VERSION "RLDCU"

NS_ :

BS_:

BU_: RLDCU

BO_ 3221225472 VECTOR__INDEPENDENT_SIG_MSG: 0 Vector__XXX
 SG_ CrashOtptSts : 0|8@0+ (1,0) [0|255] "" Vector__XXX
 SG_ SigGroup_232_ChkSm : 0|8@0+ (1,0) [0|255] "" Vector__XXX
 SG_ SigGroup_232_RlngCtr : 0|4@0+ (1,0) [0|15] "" Vector__XXX

BO_ 906 XCU_BodyCMD1_100mixed_GW: 8 Vector__XXX
 SG_ SwBkLghtCmd : 22|7@0+ (1,0) [0|100] "%" Vector__XXX

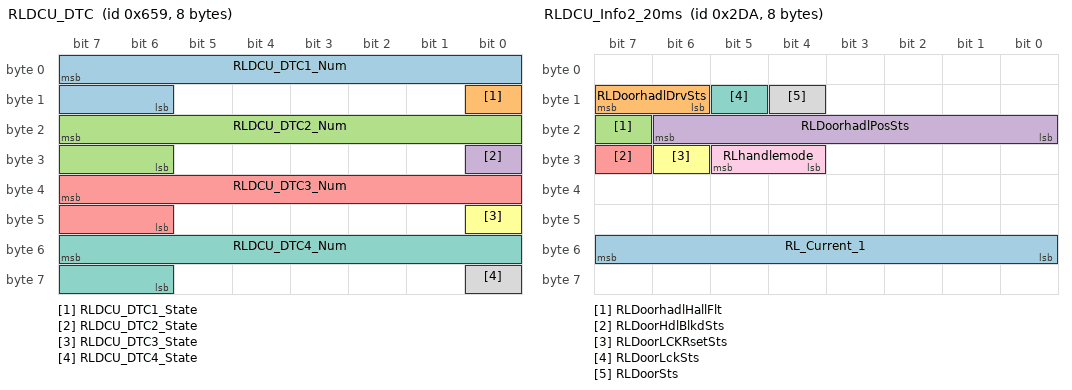
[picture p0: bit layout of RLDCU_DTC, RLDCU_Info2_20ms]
BO_ 1625 RLDCU_DTC: 8 RLDCU
 SG_ RLDCU_DTC1_Num : 7|10@0+ (1,0) [0|1023] "" Vector__XXX
 SG_ RLDCU_DTC1_State : 8|1@0+ (1,0) [0|1] "" Vector__XXX
 SG_ RLDCU_DTC2_Num : 23|10@0+ (1,0) [0|1023] "" Vector__XXX
 SG_ RLDCU_DTC2_State : 24|1@0+ (1,0) [0|1] "" Vector__XXX
 SG_ RLDCU_DTC3_Num : 39|10@0+ (1,0) [0|1023] "" Vector__XXX
 SG_ RLDCU_DTC3_State : 40|1@0+ (1,0) [0|1] "" Vector__XXX
 SG_ RLDCU_DTC4_Num : 55|10@0+ (1,0) [0|1023] "" Vector__XXX
 SG_ RLDCU_DTC4_State : 56|1@0+ (1,0) [0|1] "" Vector__XXX

BO_ 1386 RLDCU_Info1_100ms: 32 RLDCU
 SG_ LChildProtnLckDrvFlt : 34|1@0+ (1,0) [0|1] "" Vector__XXX
 SG_ LChildProtnLckDrvSts : 18|2@0+ (1,0) [0|3] "" Vector__XXX
 SG_ LChildProtnLckFlt : 16|1@0+ (1,0) [0|1] "" Vector__XXX
 SG_ LChildProtnLckSts : 23|1@0+ (1,0) [0|1] "" Vector__XXX
 SG_ LChildProtnLckThrmlProtnSts : 35|1@0+ (1,0) [0|1] "" Vector__XXX
 SG_ RLCinchabusests : 76|1@0+ (1,0) [0|1] "" Vector__XXX
 SG_ RLDCUconfigureSts : 66|3@0+ (1,0) [0|7] "" Vector__XXX
 SG_ RLDCUCrashSts : 79|1@0+ (1,0) [0|1] "" Vector__XXX
 SG_ RLDoor_BackLghtDrvSts : 57|7@0+ (1,0) [0|100] "%" Vector__XXX
 SG_ RLDoor_BackLghtFlrSts : 59|2@0+ (1,0) [0|3] "" Vector__XXX
 SG_ RLDoorCinchSts : 15|2@0+ (1,0) [0|3] "" Vector__XXX
 SG_ RLDoorHadlLghtDrvSts : 62|1@0+ (1,0) [0|1] "" Vector__XXX
 SG_ RLDoorHadlLghtFlrSts : 61|2@0+ (1,0) [0|3] "" Vector__XXX
 SG_ RLDoorhadlMotorFlt : 39|1@0+ (1,0) [0|1] "" Vector__XXX
 SG_ RLDoorLckUnlckDrvSts : 33|2@0+ (1,0) [0|3] "" Vector__XXX
 SG_ RLDoorLightSts : 78|1@0+ (1,0) [0|1] "" Vector__XXX
 SG_ RLDoorligtsFlt : 75|1@0+ (1,0) [0|1] "" Vector__XXX
 SG_ RLDoorligtsSts : 77|1@0+ (1,0) [0|1] "" Vector__XXX
 SG_ RLDoorPawlSts : 22|1@0+ (1,0) [0|1] "" Vector__XXX
 SG_ RLDoorPullCircuitFlt : 19|1@0+ (1,0) [0|1] "" Vector__XXX
 SG_ RLDoorPullDrvFlt : 20|1@0+ (1,0) [0|1] "" Vector__XXX
 SG_ RLDoorPullDrvSts : 13|2@0+ (1,0) [0|3] "" Vector__XXX
 SG_ RLDoorRatchetSts : 21|1@0+ (1,0) [0|1] "" Vector__XXX
 SG_ RLDoorThrmlProtnSts : 36|1@0+ (1,0) [0|1] "" Vector__XXX
 SG_ RLDoorUnlckCircuitFlt : 38|1@0+ (1,0) [0|1] "" Vector__XXX
 SG_ RLDoorUnlckDrvFlt : 37|1@0+ (1,0) [0|1] "" Vector__XXX
 SG_ RLDoorWinHallFlt : 74|2@0+ (1,0) [0|3] "" Vector__XXX
 SG_ RLWdwReqRes : 28|4@0+ (1,0) [0|15] "" Vector__XXX
 SG_ RLWndAnti_PnchSts : 46|1@0+ (1,0) [0|1] "" Vector__XXX
 SG_ RLWndInhSts : 63|1@0+ (1,0) [0|1] "" Vector__XXX
 SG_ RLWndInitnSts : 47|1@0+ (1,0) [0|1] "" Vector__XXX
 SG_ RLWndMotorFlt : 40|1@0+ (1,0) [0|1] "" Vector__XXX
 SG_ RLWndPcntPos : 54|7@0+ (1,0) [0|100] "%" Vector__XXX
 SG_ RLWndRunSts : 43|3@0+ (1,0) [0|7] "" Vector__XXX
 SG_ RLWndSts : 45|2@0+ (1,0) [0|3] "" Vector__XXX
 SG_ RLWndSwSts : 31|3@0+ (1,0) [0|7] "" Vector__XXX
 SG_ RLWndSwStuckFlt : 24|1@0+ (1,0) [0|1] "" Vector__XXX
 SG_ RLWndThrmlProtnSts : 55|1@0+ (1,0) [0|1] "" Vector__XXX
 SG_ SigGroup_0x56A_ChkSm : 7|8@0+ (1,0) [0|255] "" Vector__XXX
 SG_ SigGroup_0x56A_RlngCtr : 11|4@0+ (1,0) [0|15] "" Vector__XXX

BO_ 730 RLDCU_Info2_20ms: 8 RLDCU
 SG_ RL_Current_1 : 55|8@0+ (1,0) [0|255] "" Vector__XXX
 SG_ RLDoorhadlDrvSts : 15|2@0+ (1,0) [0|3] "" Vector__XXX
 SG_ RLDoorhadlHallFlt : 23|1@0+ (1,0) [0|1] "" Vector__XXX
 SG_ RLDoorhadlPosSts : 22|7@0+ (1,0) [0|100] "%" Vector__XXX
 SG_ RLDoorHdlBlkdSts : 31|1@0+ (1,0) [0|1] "" Vector__XXX
 SG_ RLDoorLCKRsetSts : 30|1@0+ (1,0) [0|1] "" Vector__XXX
 SG_ RLDoorLckSts : 13|1@0+ (1,0) [0|1] "" Vector__XXX
 SG_ RLDoorSts : 12|1@0+ (1,0) [0|1] "" Vector__XXX
 SG_ RLhandlemode : 29|2@0+ (1,0) [0|3] "" Vector__XXX

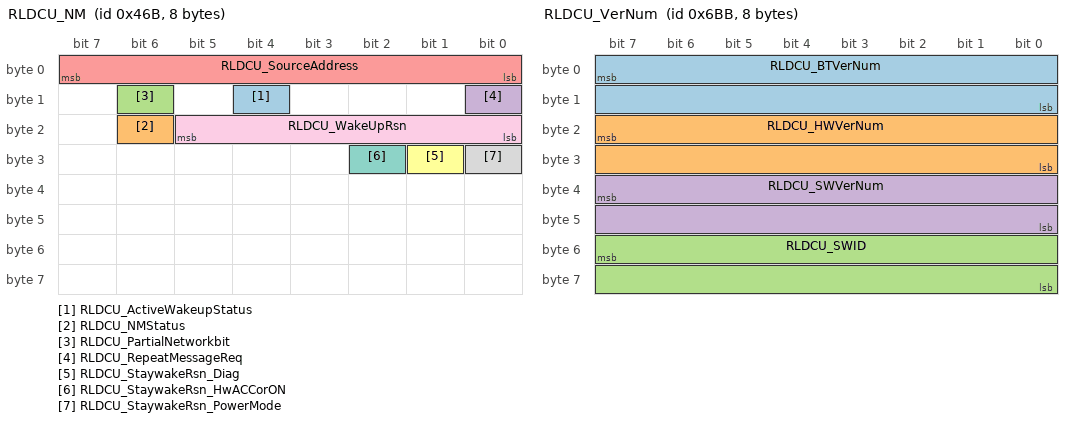
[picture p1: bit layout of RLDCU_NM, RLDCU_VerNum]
BO_ 1131 RLDCU_NM: 8 RLDCU
 SG_ RLDCU_ActiveWakeupStatus : 12|1@0+ (1,0) [0|1] "" Vector__XXX
 SG_ RLDCU_NMStatus : 22|1@0+ (1,0) [0|1] "" Vector__XXX
 SG_ RLDCU_PartialNetworkbit : 14|1@0+ (1,0) [0|1] "" Vector__XXX
 SG_ RLDCU_RepeatMessageReq : 8|1@0+ (1,0) [0|1] "" Vector__XXX
 SG_ RLDCU_SourceAddress : 7|8@0+ (1,0) [0|255] "" Vector__XXX
 SG_ RLDCU_StaywakeRsn_Diag : 25|1@0+ (1,0) [0|1] "" Vector__XXX
 SG_ RLDCU_StaywakeRsn_HwACCorON : 26|1@0+ (1,0) [0|1] "" Vector__XXX
 SG_ RLDCU_StaywakeRsn_PowerMode : 24|1@0+ (1,0) [0|1] "" Vector__XXX
 SG_ RLDCU_WakeUpRsn : 21|6@0+ (1,0) [0|63] "" Vector__XXX

BO_ 1723 RLDCU_VerNum: 8 RLDCU
 SG_ RLDCU_BTVerNum : 7|16@0+ (1,0) [0|65535] "" Vector__XXX
 SG_ RLDCU_HWVerNum : 23|16@0+ (1,0) [0|65535] "" Vector__XXX
 SG_ RLDCU_SWID : 55|16@0+ (1,0) [0|65535] "" Vector__XXX
 SG_ RLDCU_SWVerNum : 39|16@0+ (1,0) [0|65535] "" Vector__XXX

BO_ 1887 UDS_DiagResp_RLDCU_FD: 64 RLDCU

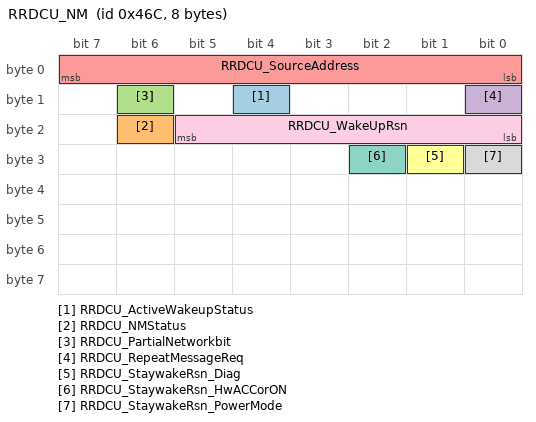
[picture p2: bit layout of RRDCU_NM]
BO_ 1132 RRDCU_NM: 8 Vector__XXX
 SG_ RRDCU_ActiveWakeupStatus : 12|1@0+ (1,0) [0|1] ""  RLDCU
 SG_ RRDCU_NMStatus : 22|1@0+ (1,0) [0|1] ""  RLDCU
 SG_ RRDCU_PartialNetworkbit : 14|1@0+ (1,0) [0|1] ""  RLDCU
 SG_ RRDCU_RepeatMessageReq : 8|1@0+ (1,0) [0|1] ""  RLDCU
 SG_ RRDCU_SourceAddress : 7|8@0+ (1,0) [0|255] ""  RLDCU
 SG_ RRDCU_StaywakeRsn_Diag : 25|1@0+ (1,0) [0|1] ""  RLDCU
 SG_ RRDCU_StaywakeRsn_HwACCorON : 26|1@0+ (1,0) [0|1] ""  RLDCU
 SG_ RRDCU_StaywakeRsn_PowerMode : 24|1@0+ (1,0) [0|1] ""  RLDCU
 SG_ RRDCU_WakeUpRsn : 21|6@0+ (1,0) [0|63] ""  RLDCU

BO_ 2015 UDS_FuncDiagReq_FD: 8 Vector__XXX

BO_ 1879 UDS_PhyDiagReq_RLDCU_FD: 64 Vector__XXX

CM_ BO_ 3221225472 "This is a message for not used signals, created by Vector CANdb++ DBC OLE DB Provider.";
CM_ SG_ 3221225472 CrashOtptSts "Crash Output Status
碰撞输出状态
注：碰撞发生后，此信号持续发送400ms（20ms间隔发送20次），之后恢复原周期（200ms）；
bit0表示前碰，bit1表示左侧碰撞，bit2表示右侧碰撞，bit3表示后碰，bit4表示翻转
则
0(00000000)表示没有碰撞，
1(00000001)表示只有前碰
2(00000010)表示只有左侧碰撞
4(00000100)表示只有右侧碰撞
8(00001000)表示只有后碰
0X10(00010000)表示翻转";
CM_ SG_ 1625 RLDCU_DTC1_Num "DTC Number
DTC序号";
CM_ SG_ 1625 RLDCU_DTC1_State "DTC State
故障状态";
CM_ SG_ 1625 RLDCU_DTC2_Num "DTC Number
DTC序号";
CM_ SG_ 1625 RLDCU_DTC2_State "DTC State
故障状态";
CM_ SG_ 1625 RLDCU_DTC3_Num "DTC Number
DTC序号";
CM_ SG_ 1625 RLDCU_DTC3_State "DTC State
故障状态";
CM_ SG_ 1625 RLDCU_DTC4_Num "DTC Number
DTC序号";
CM_ SG_ 1625 RLDCU_DTC4_State "DTC State
故障状态";
CM_ SG_ 1386 LChildProtnLckDrvFlt "Left child Protection lock  drive Fault
左侧儿童锁驱动故障";
CM_ SG_ 1386 LChildProtnLckDrvSts "Left child Protection lock  drive status
左侧儿童锁驱动状态";
CM_ SG_ 1386 LChildProtnLckFlt "left child Protection lock fault
左儿童锁故障";
CM_ SG_ 1386 LChildProtnLckSts "Left Child Protection Lock Status
左侧儿童锁状态";
CM_ SG_ 1386 LChildProtnLckThrmlProtnSts "Left child Protection  lock Thermal Protection State
左侧儿童锁热保护状态";
CM_ SG_ 1386 RLCinchabusests "Cinchabusests
自吸锁滥用状态";
CM_ SG_ 1386 RLDCUconfigureSts "RLDCU配置状态
RLDCUconfigureSts";
CM_ SG_ 1386 RLDCUCrashSts "碰撞状态
RLDCU Crash  Sts";
CM_ SG_ 1386 RLDoor_BackLghtDrvSts "Rear  Left Door Back Light DrvSts
左后门背光驱动状态";
CM_ SG_ 1386 RLDoor_BackLghtFlrSts "Rear Left Door Back Light FlrSts
左后门背光故障状态";
CM_ SG_ 1386 RLDoorCinchSts "Rear Left Door Cinch Status";
CM_ SG_ 1386 RLDoorHadlLghtDrvSts "Rear Left Door Handle LightDriveStaus
左后门把手灯驱动状态";
CM_ SG_ 1386 RLDoorHadlLghtFlrSts "Rear Left Door Handle LightFailureStaus
左后门把手灯故障状态";
CM_ SG_ 1386 RLDoorhadlMotorFlt "左后门把手电机故障
Rear Left Door Handle Motor Fault";
CM_ SG_ 1386 RLDoorLckUnlckDrvSts "Rear Left Door Lock Unlock Drive Status
左后门解闭锁驱动状态";
CM_ SG_ 1386 RLDoorLightSts "左后门灯状态
RLDoorLightSts";
CM_ SG_ 1386 RLDoorligtsFlt "RLDoorligtsFlt
门灯故障状态";
CM_ SG_ 1386 RLDoorligtsSts "RLDoorligtsSts
门灯状态";
CM_ SG_ 1386 RLDoorPawlSts "Rear Left Door Pawl Status
左后锁棘爪状态";
CM_ SG_ 1386 RLDoorPullCircuitFlt "Rear Left Door Pull Circuit Fault
左后门自吸电路故障";
CM_ SG_ 1386 RLDoorPullDrvFlt "Rear Left Door Pull Drive Fault
左后门自吸驱动故障";
CM_ SG_ 1386 RLDoorPullDrvSts "Rear Left Door Pull Drive Status
左后自吸驱动状态";
CM_ SG_ 1386 RLDoorRatchetSts "Rear Left Door Ratchet Status
左后门锁棘轮状态";
CM_ SG_ 1386 RLDoorThrmlProtnSts "Rear Left Door Thermal Protection State
左后门锁热保护状态";
CM_ SG_ 1386 RLDoorUnlckCircuitFlt "Rear Left Door Unlock Circuit Fault
左后门锁解锁电路故障";
CM_ SG_ 1386 RLDoorUnlckDrvFlt "Rear Left Door Unlock Drive Fault
左后门解锁驱动故障";
CM_ SG_ 1386 RLDoorWinHallFlt "左后车窗霍尔故障状态
RL Door Windows Hall Fault status";
CM_ SG_ 1386 RLWdwReqRes "Rear Left Window Request Result
左后车窗请求结果";
CM_ SG_ 1386 RLWndAnti_PnchSts "Rear Left windowAnti_Pinch Status
左后车窗防夹触发";
CM_ SG_ 1386 RLWndInhSts "Rear Left Window Inhibit Status
左后车窗防夹抑制状态";
CM_ SG_ 1386 RLWndInitnSts "Rear Left Window Initialization Status
左后车窗初始化状态";
CM_ SG_ 1386 RLWndMotorFlt "Rear Left Window Motor Fault
左后车窗电机故障状态";
CM_ SG_ 1386 RLWndPcntPos "Rear Left Window Percentage Position
左后车窗开度0%(全关)100%(全开)";
CM_ SG_ 1386 RLWndRunSts "Rear Left Window Run Status
左后车窗运行状态";
CM_ SG_ 1386 RLWndSts "Rear Left Window Status
左后车窗状态";
CM_ SG_ 1386 RLWndSwSts "Rear Left Window Switch Status
本地左后车窗开关";
CM_ SG_ 1386 RLWndSwStuckFlt "Rear Left Window Switch Stuck Fault
本地左后车窗开关粘连故障";
CM_ SG_ 1386 RLWndThrmlProtnSts "Rear Left Window Thermal Protection State
左后车窗热保护状态";
CM_ SG_ 1386 SigGroup_0x56A_ChkSm "CheckSum
CRC校验";
CM_ SG_ 1386 SigGroup_0x56A_RlngCtr "RollingCounter
滚动计数器";
CM_ SG_ 730 RL_Current_1 "左后电流值1";
CM_ SG_ 730 RLDoorhadlDrvSts "左后门把手驱动状态
Rear Left Door Handle Drive Status";
CM_ SG_ 730 RLDoorhadlHallFlt "左后门把手霍尔故障状态
Rear Left Door Handle Hall Fault status";
CM_ SG_ 730 RLDoorhadlPosSts "Rear Left Door Handle Pos status
左后门把手位置状态0%(全关)100%(全开)";
CM_ SG_ 730 RLDoorHdlBlkdSts "Rear Left  Door Handle Blocked Status 左后门把手受阻信号";
CM_ SG_ 730 RLDoorLCKRsetSts "RLDoorLCKRsetSts
左后自吸锁复位状态";
CM_ SG_ 730 RLDoorLckSts "Rear Left Door Lock Status
左后门锁状态信号";
CM_ SG_ 730 RLDoorSts "Rear Left Door Status
左后门状态信号";
CM_ SG_ 730 RLhandlemode "RL把手模式
handlemode";
CM_ SG_ 1131 RLDCU_ActiveWakeupStatus "Active Wakeup Bit
主动唤醒标志位";
CM_ SG_ 1131 RLDCU_NMStatus "Network Management State
指示网络管理状态";
CM_ SG_ 1131 RLDCU_PartialNetworkbit "Partial Network Bit
PN标志位";
CM_ SG_ 1131 RLDCU_RepeatMessageReq "Repeat Message Request
重复报文发送请求";
CM_ SG_ 1131 RLDCU_SourceAddress "Source ECU Address
ECU源地址";
CM_ SG_ 1131 RLDCU_StaywakeRsn_Diag "stay wake reason diagnosis
保持唤醒原因诊断模式";
CM_ SG_ 1131 RLDCU_StaywakeRsn_HwACCorON "stay wake reason hardwire ACC or ON
保持唤醒原因硬线ACC或ON有效";
CM_ SG_ 1131 RLDCU_StaywakeRsn_PowerMode "stay wake reason power mode ACC or ON
保持唤醒原因总线信号PowerMode为ACC或ON";
CM_ SG_ 1131 RLDCU_WakeUpRsn "RLDCU wake up reason
RLDCU 唤醒原因";
CM_ SG_ 1723 RLDCU_BTVerNum "BOOT Version Number
BOOT版本号";
CM_ SG_ 1723 RLDCU_HWVerNum "HardWare Version Number
硬件版本号";
CM_ SG_ 1723 RLDCU_SWID "Software ID
软件ID";
CM_ SG_ 1723 RLDCU_SWVerNum "SoftWare Version Number
软件版本号";
CM_ BO_ 1887 "当前定义的64个字节为最大诊断报文收发长度，不是固定长度，CANFD控制器应根据理想企标定义收发诊断报文";
CM_ SG_ 1132 RRDCU_ActiveWakeupStatus "Active Wakeup Bit
主动唤醒标志位";
CM_ SG_ 1132 RRDCU_NMStatus "Network Management State
指示网络管理状态";
CM_ SG_ 1132 RRDCU_PartialNetworkbit "Partial Network Bit
PN标志位";
CM_ SG_ 1132 RRDCU_RepeatMessageReq "Repeat Message Request
重复报文发送请求";
CM_ SG_ 1132 RRDCU_SourceAddress "Source ECU Address
ECU源地址";
CM_ SG_ 1132 RRDCU_StaywakeRsn_Diag "stay wake reason diagnosis
保持唤醒原因诊断模式";
CM_ SG_ 1132 RRDCU_StaywakeRsn_HwACCorON "stay wake reason hardwire ACC or ON
保持唤醒原因硬线ACC或ON有效";
CM_ SG_ 1132 RRDCU_StaywakeRsn_PowerMode "stay wake reason power mode ACC or ON
保持唤醒原因总线信号PowerMode为ACC或ON";
CM_ SG_ 1132 RRDCU_WakeUpRsn "RRDCU wake up reason
RRDCU 唤醒原因";
CM_ BO_ 1879 "当前定义的64个字节为最大诊断报文收发长度，不是固定长度，CANFD控制器应根据理想企标定义收发诊断报文";
BA_DEF_  "BaudRateCANFD" INT 1000 10000000;
BA_DEF_  "Baudrate" INT 1000 1000000;
BA_DEF_  "BusType" STRING ;
BA_DEF_  "DBName" STRING ;
BA_DEF_  "Manufacturer" STRING ;
BA_DEF_  "NmAsrBaseAddress" HEX 0 65535;
BA_DEF_  "NmAsrCanMsgCycleTime" INT 0 65535;
BA_DEF_  "NmAsrMessageCount" INT 0 255;
BA_DEF_  "NmAsrRepeatMessageTime" INT 0 65535;
BA_DEF_  "NmAsrTimeoutTime" INT 0 65535;
BA_DEF_  "NmAsrWaitBusSleepTime" INT 0 65535;
BA_DEF_  "ProtocolType" STRING ;
BA_DEF_ BU_  "ILUsed" ENUM  "No","Yes";
BA_DEF_ BU_  "NmAsrCanMsgReducedTime" INT 0 65535;
BA_DEF_ BU_  "NmAsrNode" ENUM  "No","Yes";
BA_DEF_ BO_  "CANFD_BRS" ENUM  "0","1";
BA_DEF_ BO_  "DiagConnection" INT 0 65535;
BA_DEF_ BO_  "DiagRequest" ENUM  "No","Yes";
BA_DEF_ BO_  "DiagResponse" ENUM  "No","Yes";
BA_DEF_ BO_  "DiagState" ENUM  "No","Yes";
BA_DEF_ BO_  "GenMsgCycleTime" INT 0 300000;
BA_DEF_ BO_  "GenMsgDelayTime" INT 0 300000;
BA_DEF_ BO_  "GenMsgILSupport" ENUM  "No","Yes";
BA_DEF_ BO_  "GenMsgSendType" ENUM  "cyclic","spontaneous","cyclicIfActive","spontaneousWithDelay","cyclicAndSpontaneous","cyclicAndSpontaneousWithDelay","IfActive","NoMsgSendType";
BA_DEF_ BO_  "GenMsgStartDelayTime" INT 0 300000;
BA_DEF_ BO_  "NmAsrMessage" ENUM  "No","Yes";
BA_DEF_ BO_  "VFrameFormat" ENUM  "StandardCAN","ExtendedCAN","reserved","J1939PG","reserved","reserved","reserved","reserved","reserved","reserved","reserved","reserved","reserved","reserved","StandardCAN_FD","ExtendedCAN_FD";
BA_DEF_ SG_  "GenSigSendType" ENUM  "Cyclic","OnWrite","OnWriteWithRepetition","OnChange","OnChangeWithRepetition","IfActive","IfActiveWithRepetition","NoSigSendType";
BA_DEF_ SG_  "GenSigStartValue" INT 0 2147483647;
BA_DEF_DEF_  "BaudRateCANFD" 2000000;
BA_DEF_DEF_  "Baudrate" 500000;
BA_DEF_DEF_  "BusType" "";
BA_DEF_DEF_  "DBName" "";
BA_DEF_DEF_  "Manufacturer" "Vector";
BA_DEF_DEF_  "NmAsrBaseAddress" 1024;
BA_DEF_DEF_  "NmAsrCanMsgCycleTime" 500;
BA_DEF_DEF_  "NmAsrMessageCount" 255;
BA_DEF_DEF_  "NmAsrRepeatMessageTime" 1500;
BA_DEF_DEF_  "NmAsrTimeoutTime" 2000;
BA_DEF_DEF_  "NmAsrWaitBusSleepTime" 5000;
BA_DEF_DEF_  "ProtocolType" "";
BA_DEF_DEF_  "ILUsed" "Yes";
BA_DEF_DEF_  "NmAsrCanMsgReducedTime" 50;
BA_DEF_DEF_  "NmAsrNode" "Yes";
BA_DEF_DEF_  "CANFD_BRS" "1";
BA_DEF_DEF_  "DiagConnection" 57346;
BA_DEF_DEF_  "DiagRequest" "No";
BA_DEF_DEF_  "DiagResponse" "No";
BA_DEF_DEF_  "DiagState" "No";
BA_DEF_DEF_  "GenMsgCycleTime" 0;
BA_DEF_DEF_  "GenMsgDelayTime" 0;
BA_DEF_DEF_  "GenMsgILSupport" "Yes";
BA_DEF_DEF_  "GenMsgSendType" "";
BA_DEF_DEF_  "GenMsgStartDelayTime" 0;
BA_DEF_DEF_  "NmAsrMessage" "No";
BA_DEF_DEF_  "VFrameFormat" "J1939PG";
BA_DEF_DEF_  "GenSigSendType" "Cyclic";
BA_DEF_DEF_  "GenSigStartValue" 0;
BA_ "BusType" "CAN FD";
BA_ "ProtocolType" "CAN";
BA_ "DBName" "RLDCU_BDCAN1_Ctrl";
BA_ "VFrameFormat" BO_ 906 14;
BA_ "GenMsgCycleTime" BO_ 1625 1000;
BA_ "GenMsgSendType" BO_ 1625 0;
BA_ "VFrameFormat" BO_ 1625 14;
BA_ "GenMsgCycleTime" BO_ 1386 100;
BA_ "GenMsgSendType" BO_ 1386 0;
BA_ "GenMsgStartDelayTime" BO_ 1386 10;
BA_ "VFrameFormat" BO_ 1386 14;
BA_ "GenMsgCycleTime" BO_ 730 20;
BA_ "GenMsgSendType" BO_ 730 0;
BA_ "VFrameFormat" BO_ 730 14;
BA_ "GenMsgDelayTime" BO_ 1131 500;
BA_ "GenMsgSendType" BO_ 1131 1;
BA_ "NmAsrMessage" BO_ 1131 1;
BA_ "VFrameFormat" BO_ 1131 0;
BA_ "GenMsgCycleTime" BO_ 1723 5000;
BA_ "GenMsgSendType" BO_ 1723 0;
BA_ "GenMsgStartDelayTime" BO_ 1723 50;
BA_ "VFrameFormat" BO_ 1723 14;
BA_ "DiagConnection" BO_ 1887 37;
BA_ "DiagResponse" BO_ 1887 1;
BA_ "GenMsgDelayTime" BO_ 1887 20;
BA_ "GenMsgSendType" BO_ 1887 1;
BA_ "VFrameFormat" BO_ 1887 14;
BA_ "GenMsgDelayTime" BO_ 1132 500;
BA_ "GenMsgSendType" BO_ 1132 1;
BA_ "NmAsrMessage" BO_ 1132 1;
BA_ "VFrameFormat" BO_ 1132 0;
BA_ "DiagConnection" BO_ 2015 49;
BA_ "DiagState" BO_ 2015 1;
BA_ "GenMsgDelayTime" BO_ 2015 20;
BA_ "GenMsgSendType" BO_ 2015 1;
BA_ "VFrameFormat" BO_ 2015 14;
BA_ "DiagConnection" BO_ 1879 37;
BA_ "DiagRequest" BO_ 1879 1;
BA_ "GenMsgDelayTime" BO_ 1879 20;
BA_ "GenMsgSendType" BO_ 1879 1;
BA_ "VFrameFormat" BO_ 1879 14;
BA_ "GenSigSendType" SG_ 3221225472 CrashOtptSts 2;
BA_ "GenSigStartValue" SG_ 1386 RLWndPcntPos 127;
BA_ "GenSigStartValue" SG_ 1386 RLWndRunSts 3;
BA_ "GenSigStartValue" SG_ 1386 RLWndSts 3;
BA_ "GenSigSendType" SG_ 1131 RLDCU_ActiveWakeupStatus 1;
BA_ "GenSigSendType" SG_ 1131 RLDCU_NMStatus 1;
BA_ "GenSigSendType" SG_ 1131 RLDCU_PartialNetworkbit 1;
BA_ "GenSigSendType" SG_ 1131 RLDCU_RepeatMessageReq 1;
BA_ "GenSigSendType" SG_ 1131 RLDCU_SourceAddress 1;
BA_ "GenSigSendType" SG_ 1131 RLDCU_StaywakeRsn_Diag 1;
BA_ "GenSigSendType" SG_ 1131 RLDCU_StaywakeRsn_HwACCorON 1;
BA_ "GenSigSendType" SG_ 1131 RLDCU_StaywakeRsn_PowerMode 1;
BA_ "GenSigSendType" SG_ 1131 RLDCU_WakeUpRsn 1;
BA_ "GenSigStartValue" SG_ 1723 RLDCU_SWID 65535;
BA_ "GenSigSendType" SG_ 1132 RRDCU_ActiveWakeupStatus 1;
BA_ "GenSigSendType" SG_ 1132 RRDCU_NMStatus 1;
BA_ "GenSigSendType" SG_ 1132 RRDCU_PartialNetworkbit 1;
BA_ "GenSigSendType" SG_ 1132 RRDCU_RepeatMessageReq 1;
BA_ "GenSigSendType" SG_ 1132 RRDCU_SourceAddress 1;
BA_ "GenSigSendType" SG_ 1132 RRDCU_StaywakeRsn_Diag 1;
BA_ "GenSigSendType" SG_ 1132 RRDCU_StaywakeRsn_HwACCorON 1;
BA_ "GenSigSendType" SG_ 1132 RRDCU_StaywakeRsn_PowerMode 1;
BA_ "GenSigSendType" SG_ 1132 RRDCU_WakeUpRsn 1;
VAL_ 3221225472 CrashOtptSts 0 "NoDplCrsh" 1 "FrtDplCrsh" 2 "DrvrDplCrsh" 3 "Drvr_FrtDplCrsh" 4 "PsngDplCrsh" 5 "PsngFrtDplCrsh" 6 "Drvr_PsngDplCrsh" 7 "Drvr_Psng_FrtDplCrsh" 8 "Rr_DplCrsh" 9 "Rr_FrtDplCrsh" 10 "Rr_DrvrDplCrsh" 11 "Rr_Drvr_FrtDplCrsh" 12 "Rr_PsngDplCrsh" 13 "Rr_Psng_FrtDplCrsh" 14 "Rr_Psng_DrvrDplCrsh" 15 "Rr_Psng_Drv_FrtDplCrsh" 16 "Rlov_DplCrsh" 17 "Rlov_FrtDplCrsh" 18 "Rlov_DrvrSideDplCrsh" 19 "Rlov_Drvr_FrtDplCrsh" 20 "Rlov_PsngDpl Crsh" 21 "Rlov_Psng_FrtDplCrsh" 22 "Rlov_Psng_DrvrDplCrsh" 23 "Rlov_Psng_Drvr_FrtDplCrsh" 24 "Rlov_RrSideDplCrsh" 25 "Rlov_Rr_FrtDplCrsh" 26 "Rlov_Rr_DrvrDplCrsh" 27 "Rlov_Rr_Drvr_FrtDplCrsh" 28 "Rlov_Rr_PsngDplCrsh" 29 "Rlov_Rr_Psng_FrtDplCrsh" 30 "Rlov_Rr_Psng_DrvrDplCrsh" 31 "Rlov_Rr_Psng_Drvr_FrtDplCrsh" 255 "Invalid" ;
VAL_ 1625 RLDCU_DTC1_State 0 "Normal" 1 "Fault" ;
VAL_ 1625 RLDCU_DTC2_State 0 "Normal" 1 "Fault" ;
VAL_ 1625 RLDCU_DTC3_State 0 "Normal" 1 "Fault" ;
VAL_ 1625 RLDCU_DTC4_State 0 "Normal" 1 "Fault" ;
VAL_ 1386 LChildProtnLckDrvFlt 0 "Normal" 1 "Failure" ;
VAL_ 1386 LChildProtnLckDrvSts 0 "Inactive" 1 "lock" 2 "unlock" 3 "reserve" ;
VAL_ 1386 LChildProtnLckFlt 0 "Normal" 1 "Failure" ;
VAL_ 1386 LChildProtnLckSts 0 "Unlocked
" 1 "Locked" ;
VAL_ 1386 LChildProtnLckThrmlProtnSts 0 "No Error" 1 "Error" ;
VAL_ 1386 RLCinchabusests 0 "normal" 1 "active" ;
VAL_ 1386 RLDCUconfigureSts 0 "X01" 1 "X02" 2 "X03" ;
VAL_ 1386 RLDCUCrashSts 0 "NO crash" 1 "crash" ;
VAL_ 1386 RLDoor_BackLghtDrvSts 127 "Invalid" ;
VAL_ 1386 RLDoor_BackLghtFlrSts 0 "No Failure" 1 "Open Circuit" 2 "Short Circuit" 3 "Reserved" ;
VAL_ 1386 RLDoorCinchSts 0 "Locked" 1 "Cinching" 2 "Semi-lock" 3 "Unlocked" ;
VAL_ 1386 RLDoorHadlLghtDrvSts 0 "Inactive" 1 "Active" ;
VAL_ 1386 RLDoorHadlLghtFlrSts 0 "No Failure" 1 "Open Circuit" 2 "Short Circuit" 3 "Reserved" ;
VAL_ 1386 RLDoorhadlMotorFlt 0 "Normal" 1 "Failure" ;
VAL_ 1386 RLDoorLckUnlckDrvSts 0 "Inactive" 1 "lock" 2 "unlock" 3 "reserve" ;
VAL_ 1386 RLDoorLightSts 0 "OFF" 1 "ON" ;
VAL_ 1386 RLDoorligtsFlt 0 "Normal" 1 "Fault" ;
VAL_ 1386 RLDoorligtsSts 0 "OFF" 1 "ON" ;
VAL_ 1386 RLDoorPawlSts 0 "Closed" 1 "Ajar" ;
VAL_ 1386 RLDoorPullCircuitFlt 0 "Normal" 1 "Failure" ;
VAL_ 1386 RLDoorPullDrvFlt 0 "Normal" 1 "Failure" ;
VAL_ 1386 RLDoorPullDrvSts 0 "Stop" 1 "Forward Driving" 2 "Reverse Driving" 3 "Pull in disabled" ;
VAL_ 1386 RLDoorRatchetSts 0 "Closed" 1 "Ajar" ;
VAL_ 1386 RLDoorThrmlProtnSts 0 "No Error" 1 "Error" ;
VAL_ 1386 RLDoorUnlckCircuitFlt 0 "Normal" 1 "Failure" ;
VAL_ 1386 RLDoorUnlckDrvFlt 0 "Normal" 1 "Failure" ;
VAL_ 1386 RLDoorWinHallFlt 0 "Normal" 1 "1 hall Fault" 2 "2 hall Fault" 3 "all hall Fault" ;
VAL_ 1386 RLWdwReqRes 0 "No Demand" 1 "Success" 2 "Fail" 3 "In Responding" 4 "Stop By Local SW" 5 "Stop By Anti-Reverse" 6 "Stop By System Fault" ;
VAL_ 1386 RLWndAnti_PnchSts 0 "Non anti_pinch status" 1 "In Anti_pinch status" ;
VAL_ 1386 RLWndInhSts 0 "Not Obs Inhibit status" 1 "Obs Inhibit status" ;
VAL_ 1386 RLWndInitnSts 0 "No Init" 1 "Init" ;
VAL_ 1386 RLWndMotorFlt 0 "No Error" 1 "Error" ;
VAL_ 1386 RLWndPcntPos 127 "Invalid" ;
VAL_ 1386 RLWndRunSts 0 "Window stop" 1 "Manual Up" 2 "Manual Down" 3 "Auto Up" 4 "Auto Down" ;
VAL_ 1386 RLWndSts 0 "Middle position" 1 "Complete Open" 2 "Complete Close" 3 "Invalid" ;
VAL_ 1386 RLWndSwSts 0 "No Requst
" 1 "Manual Up
" 2 "Auto Up
" 3 "Manual Down
" 4 "Auto Down
" 5 "Reserved
" 6 "Reserved
" 7 "Reserved" ;
VAL_ 1386 RLWndSwStuckFlt 0 "Normal" 1 "Failure" ;
VAL_ 1386 RLWndThrmlProtnSts 0 "No Error" 1 "Error" ;
VAL_ 730 RLDoorhadlDrvSts 0 "Inactive" 1 "Extend" 2 "retract" 3 "reserve" ;
VAL_ 730 RLDoorhadlHallFlt 0 "Normal" 1 "Fault" ;
VAL_ 730 RLDoorhadlPosSts 127 "invalid" ;
VAL_ 730 RLDoorHdlBlkdSts 0 "Normal" 1 "Blocked" ;
VAL_ 730 RLDoorLCKRsetSts 0 "Inactive" 1 "Active" ;
VAL_ 730 RLDoorLckSts 0 "Locked
" 1 "Unlocked" ;
VAL_ 730 RLDoorSts 0 "Closed
" 1 "Ajar" ;
VAL_ 730 RLhandlemode 0 "normal" 1 "Ice_bra mode" 2 "Uninitialized" ;
VAL_ 1131 RLDCU_ActiveWakeupStatus 0 "No active wakeup" 1 "Active Wake up" ;
VAL_ 1131 RLDCU_NMStatus 0 "RepeatMessageState" 1 "OtherOperationState" ;
VAL_ 1131 RLDCU_PartialNetworkbit 0 "Not PN" 1 "PN" ;
VAL_ 1131 RLDCU_RepeatMessageReq 0 "Not Requested" 1 "Requested" ;
VAL_ 1131 RLDCU_StaywakeRsn_Diag 0 "Inactive" 1 "Active" ;
VAL_ 1131 RLDCU_StaywakeRsn_HwACCorON 0 "Inactive" 1 "Active" ;
VAL_ 1131 RLDCU_StaywakeRsn_PowerMode 0 "Inactive" 1 "Active" ;
VAL_ 1131 RLDCU_WakeUpRsn 0 "Init" 1 "NMPDUReceived" 2 "Hardwire active" 3 "The door lock status has changed" 4 "The door status has changed" 5 "The state of the pullin lock pawl has changed" 6 "The state of the pullin lock ratchet has changed" ;
VAL_ 1132 RRDCU_ActiveWakeupStatus 0 "No active wakeup" 1 "Active Wake up" ;
VAL_ 1132 RRDCU_NMStatus 0 "RepeatMessageState" 1 "OtherOperationState" ;
VAL_ 1132 RRDCU_PartialNetworkbit 0 "Not PN" 1 "PN" ;
VAL_ 1132 RRDCU_RepeatMessageReq 0 "Not Requested" 1 "Requested" ;
VAL_ 1132 RRDCU_StaywakeRsn_Diag 0 "Inactive" 1 "Active" ;
VAL_ 1132 RRDCU_StaywakeRsn_HwACCorON 0 "Inactive" 1 "Active" ;
VAL_ 1132 RRDCU_StaywakeRsn_PowerMode 0 "Inactive" 1 "Active" ;
VAL_ 1132 RRDCU_WakeUpRsn 0 "Init" 1 "NMPDUReceived" 2 "Hardwire active" 3 "The door lock status has changed" 4 "The door status has changed" 5 "The state of the pullin lock pawl has changed" 6 "The state of the pullin lock ratchet has changed" ;
